# ESP32-P4-LP register map
Vendor: ESPRESSIF SYSTEMS (SHANGHAI) CO., LTD.; Series: ESP32 P-Series; File version: 3
CPU: RV32IMAC r0p0, little endian, no MPU, no FPU, 0 interrupt priority bits
Address unit: 32 bits
Registers are 32-bit, read-write, reset 0x0 unless marked. A register's access mark holds for its fields unless they carry their own. Offsets are from the block's base; [hi:lo] are bit positions; {n}, {i} and the like mark numbered series.

## LP_MAILBOX
Base 0x50118000
{0x0+4i} MB_MESSAGE_{i} (i=0..15) — MB_MASSEGE_0
  [31:0] MB_MESSAGE_0
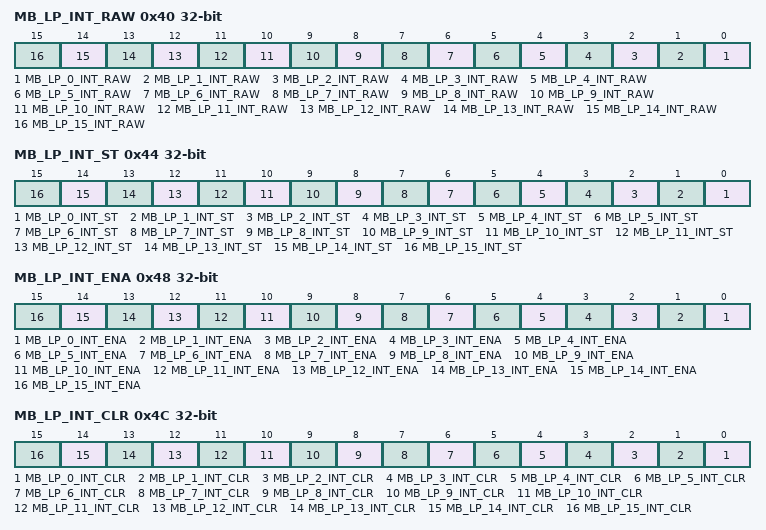
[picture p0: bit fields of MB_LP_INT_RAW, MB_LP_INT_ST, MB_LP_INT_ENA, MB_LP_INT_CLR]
0x40 MB_LP_INT_RAW ro
  [n] MB_LP_{n}_INT_RAW (n=0..15)
0x44 MB_LP_INT_ST ro
  [n] MB_LP_{n}_INT_ST (n=0..15)
0x48 MB_LP_INT_ENA
  [n] MB_LP_{n}_INT_ENA (n=0..15)
0x4C MB_LP_INT_CLR wo
  [n] MB_LP_{n}_INT_CLR (n=0..15)
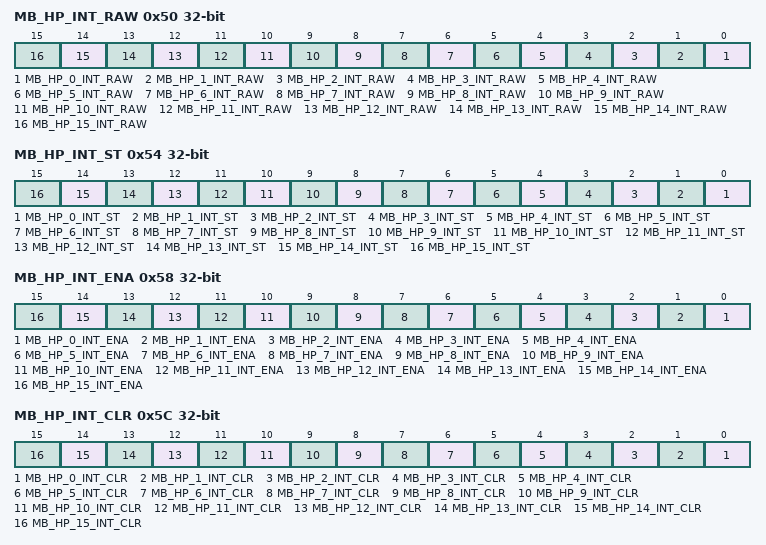
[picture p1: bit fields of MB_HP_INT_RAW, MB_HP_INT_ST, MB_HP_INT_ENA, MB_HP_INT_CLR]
0x50 MB_HP_INT_RAW ro
  [n] MB_HP_{n}_INT_RAW (n=0..15)
0x54 MB_HP_INT_ST ro
  [n] MB_HP_{n}_INT_ST (n=0..15)
0x58 MB_HP_INT_ENA
  [n] MB_HP_{n}_INT_ENA (n=0..15)
0x5C MB_HP_INT_CLR wo
  [n] MB_HP_{n}_INT_CLR (n=0..15)
0x60 MB_REG_CLK_EN
  [0] MB_REG_CLK_EN

## LP_PERI — LP_PERI Peripheral
Base 0x50120000
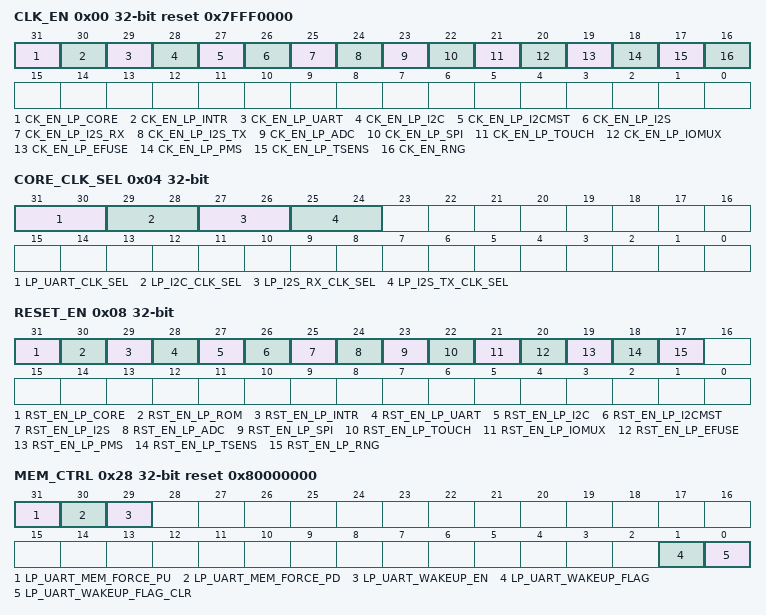
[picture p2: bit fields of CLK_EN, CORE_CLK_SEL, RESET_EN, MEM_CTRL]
0x00 CLK_EN reset 0x7FFF0000 — need_des
  [31] CK_EN_LP_CORE — write 1 to force on lp_core clk
  [30] CK_EN_LP_INTR — need_des
  [29] CK_EN_LP_UART — need_des
  [28] CK_EN_LP_I2C — need_des
  [27] CK_EN_LP_I2CMST — need_des
  [26] CK_EN_LP_I2S — need_des
  [25] CK_EN_LP_I2S_RX — need_des
  [24] CK_EN_LP_I2S_TX — need_des
  [23] CK_EN_LP_ADC — need_des
  [22] CK_EN_LP_SPI — need_des
  [21] CK_EN_LP_TOUCH — need_des
  [20] CK_EN_LP_IOMUX — need_des
  [19] CK_EN_LP_EFUSE — need_des
  [18] CK_EN_LP_PMS — need_des
  [17] CK_EN_LP_TSENS — need_des
  [16] CK_EN_RNG — need_des
0x04 CORE_CLK_SEL — need_des
  [31:30] LP_UART_CLK_SEL — need_des
  [29:28] LP_I2C_CLK_SEL — need_des
  [27:26] LP_I2S_RX_CLK_SEL — need_des
  [25:24] LP_I2S_TX_CLK_SEL — need_des
0x08 RESET_EN access per field — need_des
  [31] RST_EN_LP_CORE wo — need_des
  [30] RST_EN_LP_ROM rw — need_des
  [29] RST_EN_LP_INTR rw — need_des
  [28] RST_EN_LP_UART rw — need_des
  [27] RST_EN_LP_I2C rw — need_des
  [26] RST_EN_LP_I2CMST rw — need_des
  [25] RST_EN_LP_I2S rw — need_des
  [24] RST_EN_LP_ADC rw — need_des
  [23] RST_EN_LP_SPI rw — need_des
  [22] RST_EN_LP_TOUCH rw — need_des
  [21] RST_EN_LP_IOMUX rw — need_des
  [20] RST_EN_LP_EFUSE rw — need_des
  [19] RST_EN_LP_PMS rw — need_des
  [18] RST_EN_LP_TSENS rw — need_des
  [17] RST_EN_LP_RNG rw — need_des
0x0C CPU reset 0x80000000 — need_des
  [31] LPCORE_DBGM_UNAVAILABLE
0x28 MEM_CTRL access per field reset 0x80000000 — need_des
  [31] LP_UART_MEM_FORCE_PU rw — need_des
  [30] LP_UART_MEM_FORCE_PD rw — need_des
  [29] LP_UART_WAKEUP_EN rw — need_des
  [1] LP_UART_WAKEUP_FLAG rw — need_des
  [0] LP_UART_WAKEUP_FLAG_CLR wo — need_des
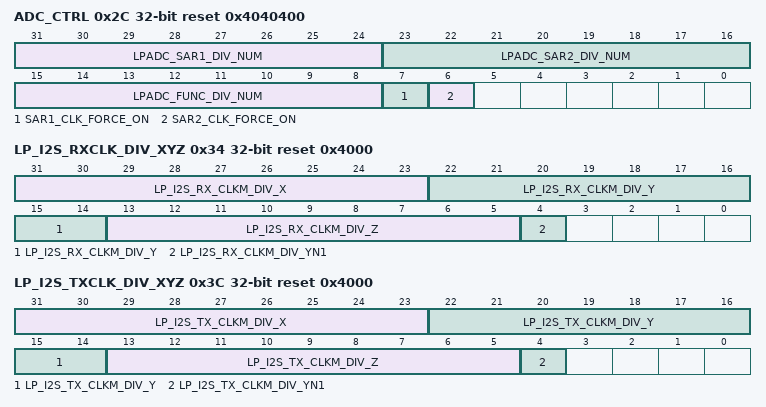
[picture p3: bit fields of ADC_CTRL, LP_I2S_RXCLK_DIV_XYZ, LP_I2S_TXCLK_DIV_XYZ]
0x2C ADC_CTRL reset 0x4040400 — need_des
  [31:24] LPADC_SAR1_DIV_NUM — need_des
  [23:16] LPADC_SAR2_DIV_NUM — need_des
  [15:8] LPADC_FUNC_DIV_NUM — need_des
  [7] SAR1_CLK_FORCE_ON — need_des
  [6] SAR2_CLK_FORCE_ON — need_des
0x30 LP_I2S_RXCLK_DIV_NUM reset 0x2000000 — need_des
  [31:24] LP_I2S_RX_CLKM_DIV_NUM
0x34 LP_I2S_RXCLK_DIV_XYZ reset 0x4000 — need_des
  [31:23] LP_I2S_RX_CLKM_DIV_X — need_des
  [22:14] LP_I2S_RX_CLKM_DIV_Y — need_des
  [13:5] LP_I2S_RX_CLKM_DIV_Z — need_des
  [4] LP_I2S_RX_CLKM_DIV_YN1 — need_des
0x38 LP_I2S_TXCLK_DIV_NUM reset 0x2000000 — need_des
  [31:24] LP_I2S_TX_CLKM_DIV_NUM
0x3C LP_I2S_TXCLK_DIV_XYZ reset 0x4000 — need_des
  [31:23] LP_I2S_TX_CLKM_DIV_X — need_des
  [22:14] LP_I2S_TX_CLKM_DIV_Y — need_des
  [13:5] LP_I2S_TX_CLKM_DIV_Z — need_des
  [4] LP_I2S_TX_CLKM_DIV_YN1 — need_des
0x3FC DATE — need_des
  [31] CLK_EN

## LP_PERI_PMS
Base 0x5012E000
0x00 TEE_PMS_DATE
  [31:0] TEE_TEE_DATE
0x04 TEE_PMS_CLK_EN
  [0] TEE_REG_CLK_EN
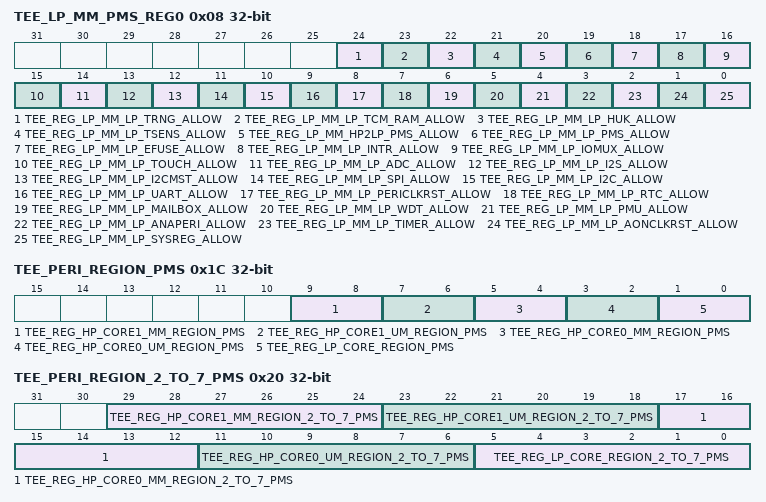
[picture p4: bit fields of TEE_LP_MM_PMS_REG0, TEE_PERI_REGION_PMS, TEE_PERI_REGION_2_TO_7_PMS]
0x08 TEE_LP_MM_PMS_REG0
  [24] TEE_REG_LP_MM_LP_TRNG_ALLOW, [23] TEE_REG_LP_MM_LP_TCM_RAM_ALLOW, [22] TEE_REG_LP_MM_LP_HUK_ALLOW, [21] TEE_REG_LP_MM_LP_TSENS_ALLOW, [20] TEE_REG_LP_MM_HP2LP_PMS_ALLOW, [19] TEE_REG_LP_MM_LP_PMS_ALLOW, [18] TEE_REG_LP_MM_LP_EFUSE_ALLOW, [17] TEE_REG_LP_MM_LP_INTR_ALLOW, [16] TEE_REG_LP_MM_LP_IOMUX_ALLOW, [15] TEE_REG_LP_MM_LP_TOUCH_ALLOW, [14] TEE_REG_LP_MM_LP_ADC_ALLOW, [13] TEE_REG_LP_MM_LP_I2S_ALLOW, [12] TEE_REG_LP_MM_LP_I2CMST_ALLOW, [11] TEE_REG_LP_MM_LP_SPI_ALLOW, [10] TEE_REG_LP_MM_LP_I2C_ALLOW, [9] TEE_REG_LP_MM_LP_UART_ALLOW, [8] TEE_REG_LP_MM_LP_PERICLKRST_ALLOW, [7] TEE_REG_LP_MM_LP_RTC_ALLOW, [6] TEE_REG_LP_MM_LP_MAILBOX_ALLOW, [5] TEE_REG_LP_MM_LP_WDT_ALLOW, [4] TEE_REG_LP_MM_LP_PMU_ALLOW, [3] TEE_REG_LP_MM_LP_ANAPERI_ALLOW, [2] TEE_REG_LP_MM_LP_TIMER_ALLOW, [1] TEE_REG_LP_MM_LP_AONCLKRST_ALLOW, [0] TEE_REG_LP_MM_LP_SYSREG_ALLOW
0x0C TEE_PERI_REGION0_LOW
  [31:2] TEE_REG_PERI_REGION0_LOW
0x10 TEE_PERI_REGION0_HIGH
  [31:2] TEE_REG_PERI_REGION0_HIGH
0x14 TEE_PERI_REGION1_LOW
  [31:2] TEE_REG_PERI_REGION1_LOW
0x18 TEE_PERI_REGION1_HIGH
  [31:2] TEE_REG_PERI_REGION1_HIGH
0x1C TEE_PERI_REGION_PMS
  [9:8] TEE_REG_HP_CORE1_MM_REGION_PMS, [7:6] TEE_REG_HP_CORE1_UM_REGION_PMS, [5:4] TEE_REG_HP_CORE0_MM_REGION_PMS, [3:2] TEE_REG_HP_CORE0_UM_REGION_PMS, [1:0] TEE_REG_LP_CORE_REGION_PMS
0x20 TEE_PERI_REGION_2_TO_7_PMS
  [29:24] TEE_REG_HP_CORE1_MM_REGION_2_TO_7_PMS, [23:18] TEE_REG_HP_CORE1_UM_REGION_2_TO_7_PMS, [17:12] TEE_REG_HP_CORE0_MM_REGION_2_TO_7_PMS, [11:6] TEE_REG_HP_CORE0_UM_REGION_2_TO_7_PMS, [5:0] TEE_REG_LP_CORE_REGION_2_TO_7_PMS
{0x14+8i} TEE_PERI_REGION{i}_LOW (i=2..7)
  [31:2] TEE_REG_PERI_REGION{i}_LOW
{0x18+8i} TEE_PERI_REGION{i}_HIGH (i=2..7)
  [31:2] TEE_REG_PERI_REGION{i}_HIGH
